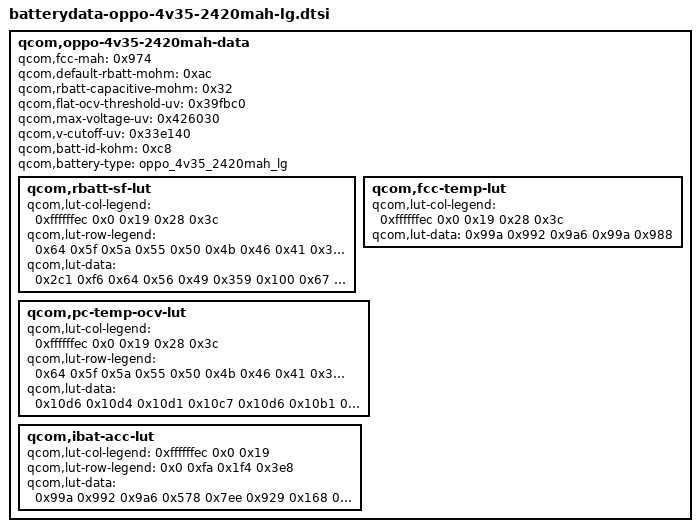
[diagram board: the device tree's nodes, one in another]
/* Copyright (c) 2020, The Linux Foundation. All rights reserved.
*  Copyright (c) 2020, the_shahnawaz_sheikh (sheikhshahnawaz41299).
*
* This program is free software; you can redistribute it and/or modify
* it under the terms of the GNU General Public License version 2 and
* only version 2 as published by the Free Software Foundation.
*
* This program is distributed in the hope that it will be useful,
* but WITHOUT ANY WARRANTY; without even the implied warranty of
* MERCHANTABILITY or FITNESS FOR A PARTICULAR PURPOSE.  See the
* GNU General Public License for more details.
*/

		qcom,oppo-4v35-2420mah-data {
			qcom,fcc-mah = <0x974>;
			qcom,default-rbatt-mohm = <0xac>;
			qcom,rbatt-capacitive-mohm = <0x32>;
			qcom,flat-ocv-threshold-uv = <0x39fbc0>;
			qcom,max-voltage-uv = <0x426030>;
			qcom,v-cutoff-uv = <0x33e140>;
			qcom,batt-id-kohm = <0xc8>;
			qcom,battery-type = "oppo_4v35_2420mah_lg";

			qcom,rbatt-sf-lut {
				qcom,lut-col-legend = <0xffffffec 0x0 0x19 0x28 0x3c>;
				qcom,lut-row-legend = <0x64 0x5f 0x5a 0x55 0x50 0x4b 0x46 0x41 0x3c 0x37 0x32 0x2d 0x28 0x23 0x1e 0x19 0x14 0x10 0xd 0xb 0xa 0x9 0x8 0x7 0x6 0x5 0x4 0x3 0x2 0x1 0x0>;
				qcom,lut-data = <0x2c1 0xf6 0x64 0x56 0x49 0x359 0x100 0x67 0x56 0x4e 0x388 0x104 0x6b 0x58 0x4c 0x376 0x109 0x6c 0x5b 0x4e 0x33f 0x10d 0x70 0x5d 0x4f 0x350 0x115 0x75 0x5f 0x50 0x36d 0x111 0x76 0x63 0x54 0x30d 0x111 0x7c 0x69 0x56 0x32a 0x100 0x75 0x67 0x5a 0x339 0xfa 0x65 0x59 0x50 0x30c 0xf9 0x60 0x56 0x4e 0x317 0x100 0x63 0x58 0x4e 0x343 0x104 0x62 0x5a 0x4f 0x360 0x126 0x63 0x5b 0x52 0x371 0x103 0x64 0x58 0x4d 0x3c5 0x10b 0x62 0x54 0x4d 0x450 0x114 0x62 0x55 0x4d 0x43f 0x11c 0x61 0x56 0x4d 0x4a2 0x124 0x61 0x57 0x4d 0x4d1 0x12c 0x63 0x57 0x4f 0x518 0x13a 0x64 0x59 0x50 0x541 0x140 0x68 0x5d 0x52 0x569 0x153 0x6c 0x5e 0x52 0x598 0x172 0x6f 0x5d 0x52 0x60f 0x185 0x73 0x61 0x52 0x65c 0x19c 0x73 0x60 0x53 0xfd1 0x1c7 0x76 0x63 0x57 0x1d83 0x1ef 0x7d 0x65 0x5b 0x2f84 0x224 0x81 0x74 0x69 0x5ea2 0x27c 0x91 0x92 0x81 0x21053 0x1e80c 0x12c 0x125 0x12c>;
			};

			qcom,fcc-temp-lut {
				qcom,lut-col-legend = <0xffffffec 0x0 0x19 0x28 0x3c>;
				qcom,lut-data = <0x99a 0x992 0x9a6 0x99a 0x988>;
			};

			qcom,pc-temp-ocv-lut {
				qcom,lut-col-legend = <0xffffffec 0x0 0x19 0x28 0x3c>;
				qcom,lut-row-legend = <0x64 0x5f 0x5a 0x55 0x50 0x4b 0x46 0x41 0x3c 0x37 0x32 0x2d 0x28 0x23 0x1e 0x19 0x14 0x10 0xd 0xb 0xa 0x9 0x8 0x7 0x6 0x5 0x4 0x3 0x2 0x1 0x0>;
				qcom,lut-data = <0x10d6 0x10d4 0x10d1 0x10c7 0x10d6 0x10b1 0x10bf 0x10ae 0x109e 0x10a6 0x1074 0x1085 0x107c 0x1067 0x106d 0x103a 0x104f 0x104a 0x1032 0x1036 0x1002 0x101b 0x1018 0xffe 0x1004 0xfc6 0xfe4 0xfe6 0xfc5 0xfca 0xf84 0xfac 0xfc3 0xf99 0xf9f 0xf59 0xf7b 0xfa3 0xf72 0xf76 0xf35 0xf4b 0xf7b 0xf48 0xf4e 0xf14 0xf22 0xf4d 0xf17 0xf1e 0xef9 0xf05 0xf1a 0xefa 0xf01 0xee0 0xef0 0xefe 0xee0 0xeea 0xecc 0xedf 0xee9 0xece 0xed7 0xebf 0xecf 0xed7 0xec0 0xec7 0xeb6 0xec3 0xec8 0xeb0 0xeb2 0xea9 0xeba 0xebb 0xe9e 0xe94 0xe98 0xeaa 0xead 0xe8b 0xe80 0xe85 0xe90 0xe97 0xe73 0xe67 0xe78 0xe78 0xe7e 0xe5c 0xe55 0xe6f 0xe73 0xe6c 0xe56 0xe51 0xe68 0xe71 0xe64 0xe55 0xe50 0xe5b 0xe6d 0xe62 0xe52 0xe4e 0xe52 0xe68 0xe5f 0xe4e 0xe4c 0xe37 0xe62 0xe56 0xe3f 0xe3e 0xe21 0xe59 0xe46 0xe24 0xe28 0xdfe 0xe1c 0xdfd 0xdfe 0xe06 0xdce 0xded 0xdc9 0xdce 0xddd 0xd91 0xdb0 0xd83 0xd91 0xda7 0xd40 0xd5e 0xd24 0xd40 0xd01 0xcc8 0xce1 0xc81 0xcc8 0xca8 0xbb8 0xbb8 0xbb8 0xbb8 0xbb8>;
			};

			qcom,ibat-acc-lut {
				qcom,lut-col-legend = <0xffffffec 0x0 0x19>;
				qcom,lut-row-legend = <0x0 0xfa 0x1f4 0x3e8>;
				qcom,lut-data = <0x99a 0x992 0x9a6 0x578 0x7ee 0x929 0x168 0x690 0x906 0x0 0x3fc 0x898>;
			};
		};
